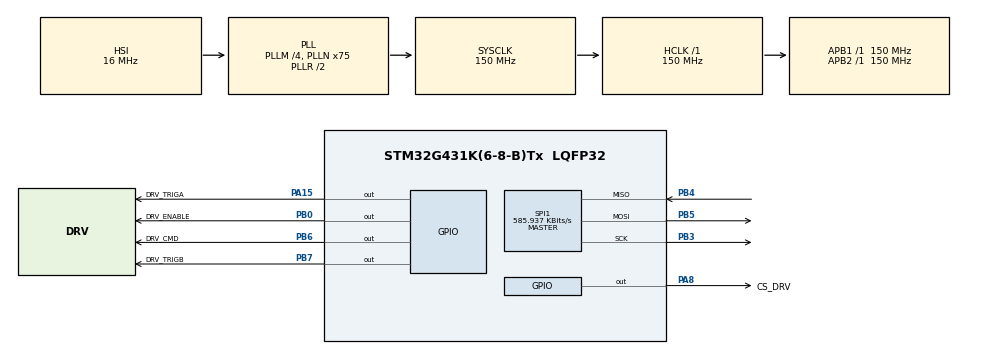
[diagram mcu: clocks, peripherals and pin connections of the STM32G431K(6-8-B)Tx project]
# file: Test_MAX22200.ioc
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Mcu.Family=STM32G4
Mcu.Name=STM32G431K(6-8-B)Tx
Mcu.Package=LQFP32
NVIC.PriorityGroup=NVIC_PRIORITYGROUP_4
PA13.Mode=Serial_Wire
PA13.Signal=SYS_JTMS-SWDIO
PA14.Mode=Serial_Wire
PA14.Signal=SYS_JTCK-SWCLK
PA15.GPIO_Label=DRV_TRIGA
PA15.Signal=GPIO_Output
PA8.GPIO_Label=CS_DRV
PA8.Signal=GPIO_Output
PB0.GPIO_Label=DRV_ENABLE
PB0.Signal=GPIO_Output
PB3.Mode=Full_Duplex_Master
PB3.Signal=SPI1_SCK
PB4.Mode=Full_Duplex_Master
PB4.Signal=SPI1_MISO
PB5.Mode=Full_Duplex_Master
PB5.Signal=SPI1_MOSI
PB6.GPIO_Label=DRV_CMD
PB6.Signal=GPIO_Output
PB7.GPIO_Label=DRV_TRIGB
PB7.Signal=GPIO_Output
ProjectManager.HeapSize=0x200
ProjectManager.StackSize=0x400
ProjectManager.TargetToolchain=STM32CubeIDE
RCC.ADC12Freq_Value=150000000
RCC.AHBFreq_Value=150000000
RCC.APB1Freq_Value=150000000
RCC.APB1TimFreq_Value=150000000
RCC.APB2Freq_Value=150000000
RCC.APB2TimFreq_Value=150000000
RCC.CortexFreq_Value=150000000
RCC.EXTERNAL_CLOCK_VALUE=12288000
RCC.HCLKFreq_Value=150000000
RCC.HSE_VALUE=8000000
RCC.HSI48_VALUE=48000000
RCC.HSI_VALUE=16000000
RCC.LSE_VALUE=32768
RCC.PLLM=RCC_PLLM_DIV4
RCC.PLLN=75
RCC.SYSCLKFreq_VALUE=150000000
RCC.SYSCLKSource=RCC_SYSCLKSOURCE_PLLCLK
RCC.USBFreq_Value=150000000
RCC.VCOOutputFreq_Value=300000000
SPI1.BaudRatePrescaler=SPI_BAUDRATEPRESCALER_256
SPI1.CLKPolarity=SPI_POLARITY_LOW
SPI1.CalculateBaudRate=585.937 KBits/s
SPI1.DataSize=SPI_DATASIZE_8BIT
SPI1.Direction=SPI_DIRECTION_2LINES
SPI1.Mode=SPI_MODE_MASTER
SPI1.VirtualType=VM_MASTER
TIM2.AutoReloadPreload=TIM_AUTORELOAD_PRELOAD_ENABLE
TIM2.PeriodNoDither=9
TIM2.Prescaler=374
VP_TIM2_VS_ClockSourceINT.Mode=Internal
board=custom

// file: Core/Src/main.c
/* USER CODE BEGIN Header */
/**
  ******************************************************************************
  * @file           : main.c
  * @brief          : Main program body
  ******************************************************************************
  * @attention
  *
  * Copyright (c) 2023 STMicroelectronics.
  * All rights reserved.
  *
  * This software is licensed under terms that can be found in the LICENSE file
  * in the root directory of this software component.
  * If no LICENSE file comes with this software, it is provided AS-IS.
  *
  ******************************************************************************
  */
/* USER CODE END Header */
#include "main.h"
#include "spi.h"
#include "tim.h"
#include "gpio.h"

/* USER CODE BEGIN PV */
uint8_t status = 0x02;

/* USER CODE END PV */

void SystemClock_Config(void);

int main(void)
{

  /* MCU Configuration--------------------------------------------------------*/

  /* Reset of all peripherals, Initializes the Flash interface and the Systick. */
  HAL_Init();

  /* Configure the system clock */
  SystemClock_Config();

  /* Initialize all configured peripherals */
  MX_GPIO_Init();
  MX_SPI1_Init();
  MX_TIM2_Init();
  /* USER CODE BEGIN 2 */
  loop_init();
  /* USER CODE END 2 */

  /* Infinite loop */
  while (1)
  {

    /* USER CODE BEGIN 3 */
  loop();

  }
  /* USER CODE END 3 */
}

void SystemClock_Config(void)
{
  RCC_OscInitTypeDef RCC_OscInitStruct = {0};
  RCC_ClkInitTypeDef RCC_ClkInitStruct = {0};

  /** Configure the main internal regulator output voltage
  */
  HAL_PWREx_ControlVoltageScaling(PWR_REGULATOR_VOLTAGE_SCALE1);

  /** Initializes the RCC Oscillators according to the specified parameters
  * in the RCC_OscInitTypeDef structure.
  */
  RCC_OscInitStruct.OscillatorType = RCC_OSCILLATORTYPE_HSI;
  RCC_OscInitStruct.HSIState = RCC_HSI_ON;
  RCC_OscInitStruct.HSICalibrationValue = RCC_HSICALIBRATION_DEFAULT;
  RCC_OscInitStruct.PLL.PLLState = RCC_PLL_ON;
  RCC_OscInitStruct.PLL.PLLSource = RCC_PLLSOURCE_HSI;
  RCC_OscInitStruct.PLL.PLLM = RCC_PLLM_DIV4;
  RCC_OscInitStruct.PLL.PLLN = 75;
  RCC_OscInitStruct.PLL.PLLP = RCC_PLLP_DIV2;
  RCC_OscInitStruct.PLL.PLLQ = RCC_PLLQ_DIV2;
  RCC_OscInitStruct.PLL.PLLR = RCC_PLLR_DIV2;
  if (HAL_RCC_OscConfig(&RCC_OscInitStruct) != HAL_OK)
  {
    Error_Handler();
  }

  /** Initializes the CPU, AHB and APB buses clocks
  */
  RCC_ClkInitStruct.ClockType = RCC_CLOCKTYPE_HCLK|RCC_CLOCKTYPE_SYSCLK
                              |RCC_CLOCKTYPE_PCLK1|RCC_CLOCKTYPE_PCLK2;
  RCC_ClkInitStruct.SYSCLKSource = RCC_SYSCLKSOURCE_PLLCLK;
  RCC_ClkInitStruct.AHBCLKDivider = RCC_SYSCLK_DIV1;
  RCC_ClkInitStruct.APB1CLKDivider = RCC_HCLK_DIV1;
  RCC_ClkInitStruct.APB2CLKDivider = RCC_HCLK_DIV1;

  if (HAL_RCC_ClockConfig(&RCC_ClkInitStruct, FLASH_LATENCY_4) != HAL_OK)
  {
    Error_Handler();
  }
}

void Error_Handler(void)
{
  __disable_irq();
  while (1)
  {
  }
}
